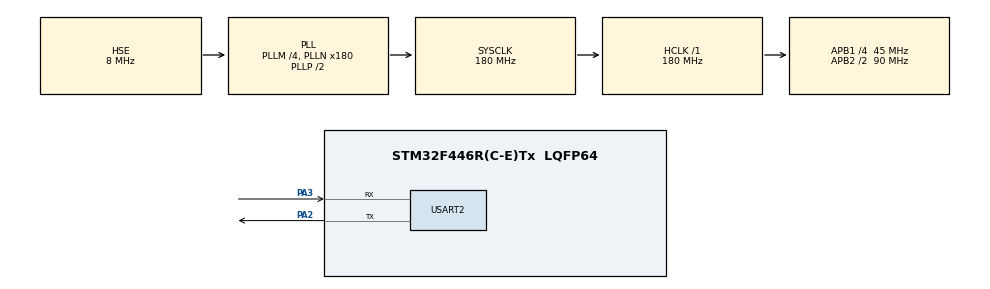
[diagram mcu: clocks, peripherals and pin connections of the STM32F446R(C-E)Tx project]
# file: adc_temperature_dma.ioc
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ADC1.Channel-0\#ChannelRegularConversion=ADC_CHANNEL_TEMPSENSOR
ADC1.NbrOfConversionFlag=1
ADC1.Rank-0\#ChannelRegularConversion=1
ADC1.SamplingTime-0\#ChannelRegularConversion=ADC_SAMPLETIME_3CYCLES
ADC1.master=1
Dma.ADC1.0.Direction=DMA_PERIPH_TO_MEMORY
Dma.ADC1.0.FIFOMode=DMA_FIFOMODE_DISABLE
Dma.ADC1.0.Instance=DMA2_Stream0
Dma.ADC1.0.MemDataAlignment=DMA_MDATAALIGN_HALFWORD
Dma.ADC1.0.MemInc=DMA_MINC_ENABLE
Dma.ADC1.0.Mode=DMA_CIRCULAR
Dma.ADC1.0.PeriphDataAlignment=DMA_PDATAALIGN_HALFWORD
Dma.ADC1.0.PeriphInc=DMA_PINC_DISABLE
Dma.ADC1.0.Priority=DMA_PRIORITY_LOW
Dma.Request0=ADC1
Mcu.Family=STM32F4
Mcu.Name=STM32F446R(C-E)Tx
Mcu.Package=LQFP64
NVIC.DMA2_Stream0_IRQn=true\:0\:0\:false\:false\:true\:false\:true\:true
NVIC.PriorityGroup=NVIC_PRIORITYGROUP_0
PA13.Mode=Serial_Wire
PA13.Signal=SYS_JTMS-SWDIO
PA14.Mode=Serial_Wire
PA14.Signal=SYS_JTCK-SWCLK
PA2.Mode=Asynchronous
PA2.Signal=USART2_TX
PA3.Mode=Asynchronous
PA3.Signal=USART2_RX
PH0-OSC_IN.Mode=HSE-External-Oscillator
PH0-OSC_IN.Signal=RCC_OSC_IN
PH1-OSC_OUT.Mode=HSE-External-Oscillator
PH1-OSC_OUT.Signal=RCC_OSC_OUT
ProjectManager.HeapSize=0x200
ProjectManager.StackSize=0x400
ProjectManager.TargetToolchain=Makefile
RCC.AHBFreq_Value=180000000
RCC.APB1CLKDivider=RCC_HCLK_DIV4
RCC.APB1Freq_Value=45000000
RCC.APB1TimFreq_Value=90000000
RCC.APB2CLKDivider=RCC_HCLK_DIV2
RCC.APB2Freq_Value=90000000
RCC.APB2TimFreq_Value=180000000
RCC.CortexFreq_Value=180000000
RCC.FLatency-AdvancedSettings=FLASH_LATENCY_5
RCC.HCLKFreq_Value=180000000
RCC.HSE_VALUE=8000000
RCC.HSI_VALUE=16000000
RCC.LSE_VALUE=32768
RCC.PLLM=4
RCC.PLLN=180
RCC.PLLSourceVirtual=RCC_PLLSOURCE_HSE
RCC.SYSCLKFreq_VALUE=180000000
RCC.SYSCLKSource=RCC_SYSCLKSOURCE_PLLCLK
RCC.USBFreq_Value=180000000
RCC.VCOOutputFreq_Value=360000000
USART2.VirtualMode=VM_ASYNC
VP_ADC1_TempSens_Input.Mode=IN-TempSens
VP_TIM2_VS_ClockSourceINT.Mode=Internal
board=NUCLEO-F446RE

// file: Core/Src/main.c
/* USER CODE BEGIN Header */
/**
  ******************************************************************************
  * @file           : main.c
  * @brief          : Main program body
  ******************************************************************************
  * @attention
  *
  * Copyright (c) 2025 STMicroelectronics.
  * All rights reserved.
  *
  * This software is licensed under terms that can be found in the LICENSE file
  * in the root directory of this software component.
  * If no LICENSE file comes with this software, it is provided AS-IS.
  *
  ******************************************************************************
  */
/* USER CODE END Header */
#include "main.h"
#include "adc.h"
#include "dma.h"
#include "tim.h"
#include "usart.h"
#include "gpio.h"

/* USER CODE BEGIN Includes */
#include <stdio.h>
#include <string.h>
/* USER CODE END Includes */

/* USER CODE BEGIN PV */
char msg[30];
uint16_t rawValues[3];
float temp;
volatile uint8_t convCompleted = 0;
/* USER CODE END PV */

void SystemClock_Config(void);

int main(void)
{

  /* MCU Configuration--------------------------------------------------------*/

  /* Reset of all peripherals, Initializes the Flash interface and the Systick. */
  HAL_Init();

  /* Configure the system clock */
  SystemClock_Config();

  /* Initialize all configured peripherals */
  MX_GPIO_Init();
  MX_DMA_Init();
  MX_ADC1_Init();
  MX_TIM2_Init();
  MX_USART2_UART_Init();
  /* USER CODE BEGIN 2 */
  HAL_TIM_Base_Start(&htim2);
  HAL_ADC_Start_DMA(&hadc1, (uint32_t*) rawValues, 3);
  /* USER CODE END 2 */

  /* Infinite loop */
  /* USER CODE BEGIN WHILE */
  while (1)
  {
    while(!convCompleted);

    for (uint8_t i = 0; i < hadc1.Init.NbrOfConversion; i++) {
      temp = ((float)rawValues[i] / 4095 * 3300);
      temp = ((temp - 760.0) / 2.5) + 25;
      int tempInt = (int)(temp * 100);

      sprintf(msg, "RawValue %d: %hu\r\n", i, rawValues[i]);
      HAL_UART_Transmit(&huart2, (uint8_t*)msg, strlen(msg), HAL_MAX_DELAY);
      sprintf(msg, "Temp %d: %d.%02d\r\n", i, tempInt / 100, tempInt % 100);
      HAL_UART_Transmit(&huart2, (uint8_t*)msg, strlen(msg), HAL_MAX_DELAY);
    }
    convCompleted = 0;
    /* USER CODE END WHILE */

  }
}

void SystemClock_Config(void)
{
  RCC_OscInitTypeDef RCC_OscInitStruct = {0};
  RCC_ClkInitTypeDef RCC_ClkInitStruct = {0};

  /** Configure the main internal regulator output voltage
  */
  __HAL_RCC_PWR_CLK_ENABLE();
  __HAL_PWR_VOLTAGESCALING_CONFIG(PWR_REGULATOR_VOLTAGE_SCALE1);

  /** Initializes the RCC Oscillators according to the specified parameters
  * in the RCC_OscInitTypeDef structure.
  */
  RCC_OscInitStruct.OscillatorType = RCC_OSCILLATORTYPE_HSE;
  RCC_OscInitStruct.HSEState = RCC_HSE_ON;
  RCC_OscInitStruct.PLL.PLLState = RCC_PLL_ON;
  RCC_OscInitStruct.PLL.PLLSource = RCC_PLLSOURCE_HSE;
  RCC_OscInitStruct.PLL.PLLM = 4;
  RCC_OscInitStruct.PLL.PLLN = 180;
  RCC_OscInitStruct.PLL.PLLP = RCC_PLLP_DIV2;
  RCC_OscInitStruct.PLL.PLLQ = 2;
  RCC_OscInitStruct.PLL.PLLR = 2;
  if (HAL_RCC_OscConfig(&RCC_OscInitStruct) != HAL_OK)
  {
    Error_Handler();
  }

  /** Activate the Over-Drive mode
  */
  if (HAL_PWREx_EnableOverDrive() != HAL_OK)
  {
    Error_Handler();
  }

  /** Initializes the CPU, AHB and APB buses clocks
  */
  RCC_ClkInitStruct.ClockType = RCC_CLOCKTYPE_HCLK|RCC_CLOCKTYPE_SYSCLK
                              |RCC_CLOCKTYPE_PCLK1|RCC_CLOCKTYPE_PCLK2;
  RCC_ClkInitStruct.SYSCLKSource = RCC_SYSCLKSOURCE_PLLCLK;
  RCC_ClkInitStruct.AHBCLKDivider = RCC_SYSCLK_DIV1;
  RCC_ClkInitStruct.APB1CLKDivider = RCC_HCLK_DIV4;
  RCC_ClkInitStruct.APB2CLKDivider = RCC_HCLK_DIV2;

  if (HAL_RCC_ClockConfig(&RCC_ClkInitStruct, FLASH_LATENCY_5) != HAL_OK)
  {
    Error_Handler();
  }
}

/* USER CODE BEGIN 4 */
void HAL_ADC_ConvCpltCallback(ADC_HandleTypeDef* hadc) {
  convCompleted = 1;
}
/* USER CODE END 4 */

void Error_Handler(void)
{
  __disable_irq();
  while (1)
  {
  }
}
